# Polarfire SoC register map
Vendor: Microchip; File version: 1.0
CPU: Microchip PolarFire SoC 1.0, little endian
Registers are 32-bit, read-write, reset 0x0 unless marked. A register's access mark holds for its fields unless they carry their own. Offsets are from the block's base; [hi:lo] are bit positions.

## GEM_A_LO (part 1 of 8) — GEM_A_LO Controller
Base 0x20110000
Same registers: GEM_B_LO 0x20112000, GEM_A_HI 0x28110000, GEM_B_HI 0x28112000
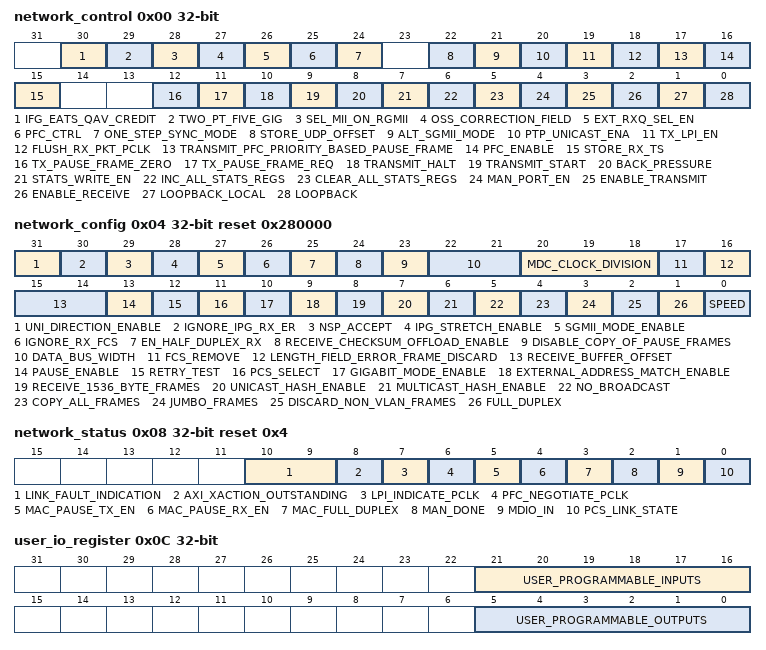
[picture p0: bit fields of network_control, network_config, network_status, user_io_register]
0x00 network_control — The network control register contains general MAC control functions for both receiver and transmitter.
  [30] IFG_EATS_QAV_CREDIT — Setting this bit high modifies the CBS algorithm so the IFG/IPG associated with a transmit frame counts towards its 802.1Qav credit.
  [29] TWO_PT_FIVE_GIG — 2.5G operation selected - setting this bit high drives the speed_mode[3] top level output pin high and also adjusts the link timer in the PCS auto-negotiation block to ensure it delivers 10ms for 2500BASE-X and 1.6ms in SGMII mode, and also ensures int_moderation counts 800ns periods with the speeded up MAC clocks.
  [28] SEL_MII_ON_RGMII — If the RGMII interface is being used, set this bit high to configure the RGMII interface for MII operation (in 802.3br configurations this bit has no effect for the eMAC).
  [27] OSS_CORRECTION_FIELD — 1588 One Step Correction Field Update. Set this bit high to enable updating the correction field of PTP 1588 version 2 sync frames by adding the current TSU timer value.
  [26] EXT_RXQ_SEL_EN — Enable external selection of receive queue. When this bit is high the ext_match1, ext_match2, ext_match3 and ext_match4 inputs will determine which receive queue a frame is routed to. This will be the case regardless of the state of the external address match enable bit 9 of the network config register. Note that receive frames will be dropped unless they are matched by the internal frame filtering functionality. If the external address match enable bit 9 in the network config register is set frames may be matched by an external address match filter as long as one of the ext_match1, ext_match2, ext_match3 and ext_match4 inputs is asserted early enough. When set ext_rxq_sel_en takes precedence over the existing screener functionality. This bit is only relevant if priority queuing is configured.
  [25] PFC_CTRL — Enable multiple PFC pause quantums, one per pause priority.
  [24] ONE_STEP_SYNC_MODE — 1588 One Step Sync Mode. Write 1 to enable. Replace timestamp field in the 1588 header for TX Sync Frames with current TSU timer value.
  [22] STORE_UDP_OFFSET — Store UDP / TCP offset to memory. Setting this bit to one will cause the upper 16-bits of the CRC of every received frame to be replaced with the offset from start of frame to the beginning of the UDP or TCP header. The lower 16-bits of the CRC are replaced with zero and reserved for future use. The offset is measured in units of 2 bytes. Set to zero for normal operation.
  [21] ALT_SGMII_MODE — Alternative sgmii mode. If asserted with sgmii_mode in the network control register the ACK bit is driven before ability detect during transfer of status information from the PHY to the MAC.
  [20] PTP_UNICAST_ENA — Enable detection of unicast PTP unicast frames.
  [19] TX_LPI_EN — Enable LPI transmission when set LPI (low power idle) is immediately transmitted. Depending on configuration LPI is indicated on the GMII, RGMII or MII interface and can be encoded by the PCS used for SGMII. LPI is transmitted even if bit 3 transmit enable is disabled. Setting this bit also sends a pause signal to the transmit datapath. In 802.3br configurations LPI can only be controlled from the pMAC.
  [18] FLUSH_RX_PKT_PCLK — Flush the next packet from the external RX DPRAM. This bit flushes the frame that is the next in line to be pushed out to the AXI interface. Writing one to this bit will only have an effect if the DMA is not currently writing a packet already stored in the DPRAM to memory.
  [17] TRANSMIT_PFC_PRIORITY_BASED_PAUSE_FRAME — Write a one to transmit PFC priority based pause frame. Takes the values stored in the Transmit PFC Pause Register.
  [16] PFC_ENABLE — Enable PFC Priority Based Pause Reception capabilities. Setting this bit will enable PFC negotiation and recognition of priority based pause frames.
  [15] STORE_RX_TS — Store receive time stamp to memory. Setting this bit to one will cause the CRC of every received frame to be replaced with the value of the nanoseconds field of the 1588 timer that was captured as the receive frame passed the message time stamp point (for releases prior to 1p10 bits 31 and 30 of the value written to the CRC field were hardwired to zero, from release 1p10 onwards these bits represent the two least significant seconds bit of the captured timer value). Set to zero for normal operation.
  [12] TX_PAUSE_FRAME_ZERO — Transmit zero quantum pause frame - writing one to this bit causes a pause frame with zero quantum to be transmitted.
  [11] TX_PAUSE_FRAME_REQ — Transmit pause frame - writing one to this bit causes a pause frame to be transmitted.
  [10] TRANSMIT_HALT — Transmit halt - writing one to this bit resets the tx_go variable and halts the dma from reading more transmit frames into the transmit SRAM buffer. Any frames already read into the transmit SRAM will still be transmitted.
  [9] TRANSMIT_START — Start transmission - writing one to this bit starts transmission.
  [8] BACK_PRESSURE — Back pressure if set in 10M or 100M half-duplex mode will force collisions on all received frames. Ignored in gigabit half-duplex mode.
  [7] STATS_WRITE_EN — Write enable for statistics registers - setting this bit to one means the statistics registers can be written for functional test purposes.
  [6] INC_ALL_STATS_REGS — Incremental statistics registers - this bit is write only. Writing a one increments all the statistics registers by one for test purposes.
  [5] CLEAR_ALL_STATS_REGS — Clear statistics registers - this bit is write only. Writing a one clears the statistics registers.
  [4] MAN_PORT_EN — Management port enable - set to one to enable the management port. When zero forces mdio to high impedance state and mdc low.
  [3] ENABLE_TRANSMIT — Transmit enable - when set, it enables the GEM transmitter to send data. When reset transmission will stop immediately, the transmit pipeline and control registers will be cleared and the transmit queue pointer register will reset to point to the start of the transmit descriptor list. This bit needs to be set before bit 9 the start transmission bit. (Setting this bit low resets the transmit queue pointer however reading the transmit queue pointer register through the APB interface may still return an old value until transmission is restarted.)
  [2] ENABLE_RECEIVE — Receive enable - when set, it enables the GEM to receive data. When reset frame reception will stop immediately and the receive pipeline will be cleared. The receive queue pointer register is unaffected.
  [1] LOOPBACK_LOCAL — Loopback local - asserts the loopback_local signal to the system clock generator. Also connects txd to rxd, tx_en to rx_dv and forces full duplex mode. If the GEM configuration contains the PCS then bit 11 of the network configuration register must be set low to disable TBI mode when in internal loopback. rx_clk and tx_clk may malfunction as the GEM is switched into and out of internal loopback. It is important that receive and transmit circuits have already been disabled when making the switch into and out of internal loopback. Local loopback functionality is optional and may not be supported by some instantiations of the GEM.
  [0] LOOPBACK — Loopback - controls the loopback output pin.
0x04 network_config reset 0x280000 — The network configuration register contains functions for setting the mode of operation for the Gigabit Ethernet MAC.
  [31] UNI_DIRECTION_ENABLE — Uni-direction-enable. When low the PCS will transmit idle symbols if the link goes down. When high the PCS can transmit frame data when the link is down.
  [30] IGNORE_IPG_RX_ER — Ignore IPG rx_er. When set rx_er has no effect on the GEMs operation when rx_dv is low. Set this when using the RGMII wrapper in half-duplex mode.
  [29] NSP_ACCEPT — Receive bad preamble. When set frames with non-standard preamble are not rejected (the first byte of preamble needs to be 55 and the last D5, bytes other than 55 or D5 may be inserted in between).
  [28] IPG_STRETCH_ENABLE — IPG stretch enable - when set the transmit IPG can be increased above 96 bit times depending on the previous frame length using the IPG stretch register.
  [27] SGMII_MODE_ENABLE — SGMII mode enable - changes behaviour of the auto-negotiation advertisement and link partner ability registers to meet the requirements of SGMII and reduces the duration of the link timer from 10 ms to 1.6 ms.
  [26] IGNORE_RX_FCS — Ignore RX FCS - when set frames with FCS/CRC errors will not be rejected. FCS error statistics will still be collected for frames with bad FCS and FCS status will be recorded in frame's DMA descriptor. For normal operation this bit must be set to zero.
  [25] EN_HALF_DUPLEX_RX — Enable frames to be received in half-duplex mode while transmitting.
  [24] RECEIVE_CHECKSUM_OFFLOAD_ENABLE — Receive checksum offload enable - when set, the receive checksum engine is enabled. Frames with bad IP, TCP or UDP checksums are discarded.
  [23] DISABLE_COPY_OF_PAUSE_FRAMES — Disable copy of pause frames - set to one to prevent pause frames being copied to memory. When set, neither control frames with type id 8808, nor pause frames with destination address 010000c28001 are copied to memory, this functionality was enhanced in release 1p09. Note that valid pause frames received will still increment pause statistics and pause the transmission of frames as required.
  [22:21] DATA_BUS_WIDTH — Data bus width - set according to AMBA (AHB/AXI) or external FIFO data bus width. The reset value for this can be changed by defining a new value for gem_dma_bus_width_def in gem_defs. Only valid bus widths may be written if the system is configured to a maximum width less than 128-bits., :00: 32 bit data bus width, :01: 64 bit AMBA (AHB/AXI) data bus width, :10: 128 bit AMBA (AHB/AXI) data bus width, :11: invalid, :Note. The reset value of this field is equal to the gem_dma_bus_width_def define, which is user configurable.
  [20:18] MDC_CLOCK_DIVISION — MDC clock division - set according to pclk speed. These three bits determine the number pclk will be divided by to generate MDC. For conformance with the 802.3 specification, MDC must not exceed 2.5 MHz (MDC is only active during MDIO read and write operations). The reset value for this can be changed by defining a new value for gem_mdc_clock_div in gem_defs.v, :000: divide pclk by 8 (pclk up to 20 MHz), :001: divide pclk by 16 (pclk up to 40 MHz), :010: divide pclk by 32 (pclk up to 80 MHz), :011: divide pclk by 48 (pclk up to 120MHz), :100: divide pclk by 64 (pclk up to 160 MHz), :101: divide pclk by 96 (pclk up to 240 MHz), :110: divide pclk by 128 (pclk up to 320 MHz), :111: divide pclk by 224 (pclk up to 540 MHz)., :Note. The reset value of this field is equal to the gem_mdc_clock_div define, which is user configurable.
  [17] FCS_REMOVE — FCS remove - setting this bit will cause received frames to be written to memory without their frame check sequence (last 4 bytes). The frame length indicated will be reduced by four bytes in this mode.
  [16] LENGTH_FIELD_ERROR_FRAME_DISCARD — Length field error frame discard - setting this bit causes frames with a measured length shorter than the extracted length field (as indicated by bytes 13 and 14 in a non-VLAN tagged frame) to be discarded. This only applies to frames with a length field less than 0x0600.
  [15:14] RECEIVE_BUFFER_OFFSET — Receive buffer offset - indicates the number of bytes by which the received data is offset from the start of the receive buffer. Note that when the define gem_pbuf_rsc has been set then these bits cannot be used.
  [13] PAUSE_ENABLE — Pause enable - when set, transmission will pause if a non-zero 802.3 classic pause frame is received and PFC has not been negotiated.
  [12] RETRY_TEST — Retry test - must be set to zero for normal operation. If set to one the backoff between collisions will always be one slot time. Setting this bit to one helps test the too many retries condition. Also used in the pause frame tests to reduce the pause counter's decrement time from 512 bit times, to every rx_clk cycle.
  [11] PCS_SELECT — PCS select - selects between MII/GMII and TBI. Must be set for SGMII operation., :0: GMII/MII interface enabled, TBI disabled, :1: TBI enabled, GMII/MII disabled, :(in 802.3br configurations this bit must be set identically in the eMAC and pMAC)
  [10] GIGABIT_MODE_ENABLE — Gigabit mode enable - setting this bit configures the GEM for 1000 Mbps operation., :0: 10/100 operation using MII or TBI interface, :1: Gigabit operation using GMII or TBI interface, :(in 802.3br configurations this bit must be set identically in the eMAC and pMAC)
  [9] EXTERNAL_ADDRESS_MATCH_ENABLE — External address match enable - when set the external address match interface can be used to copy frames to memory.
  [8] RECEIVE_1536_BYTE_FRAMES — Receive 1536 byte frames - setting this bit means the GEM will accept frames up to 1536 bytes in length. Normally the GEM would reject any frame above 1518 bytes.
  [7] UNICAST_HASH_ENABLE — Unicast hash enable - when set, unicast frames will be accepted when the 6 bit hash function of the destination address points to a bit that is set in the hash register.
  [6] MULTICAST_HASH_ENABLE — Multicast hash enable - when set, multicast frames will be accepted when the 6 bit hash function of the destination address points to a bit that is set in the hash register.
  [5] NO_BROADCAST — No broadcast - when set to logic one, frames addressed to the broadcast address of all ones will not be accepted.
  [4] COPY_ALL_FRAMES — Copy all frames - when set to logic one, all valid frames will be accepted.
  [3] JUMBO_FRAMES — Jumbo frames - set to one to enable jumbo frames up to 'gem_jumbo_max_length bytes to be accepted. The default length is 10,240 bytes.
  [2] DISCARD_NON_VLAN_FRAMES — Discard non-VLAN frames - when set only VLAN tagged frames will be passed to the address matching logic.
  [1] FULL_DUPLEX — Full duplex - if set to logic one, the transmit block ignores the state of collision and carrier sense and allows receive while transmitting. Also controls the half_duplex pin.
  [0] SPEED — Speed - set to logic one to indicate 100Mbps operation, logic zero for 10Mbps. The value of this pin is reflected on the speed_mode[0] output pin (in 802.3br configurations this bit has no effect for the eMAC).
0x08 network_status ro reset 0x4 — The network status register returns status information with respect to the PHY management MDIO interface, the PCS, priority flow control, LPI and other status.
  [10:9] LINK_FAULT_INDICATION — For 2.5GBASE-X operation these two bits return the state of link_fault in the LFSM defined in Figure 46-11 of IEEE 802.3:, : 00 - OK, : 01 - local fault, : 10 - remote fault, : 11 - link interruption, :If the link fault state machine is not enabled (by setting the 2.5G, AN enable, uni directional enable and tbi control bits) these two bits are set to zero.
  [8] AXI_XACTION_OUTSTANDING — Outstanding AXI Transactions - This status bit is set when one or more AXI read or write transactions have been issued by the DUT but the responses have not yet been fully collected.
  [7] LPI_INDICATE_PCLK — LPI Indication - Low power idle has been detected on receive. This bit is set when LPI is detected and reset when normal idle is detected. An interrupt is generated when the state of this bit changes.
  [6] PFC_NEGOTIATE_PCLK — Set when PFC Priority Based Pause has been negotiated.
  [5] MAC_PAUSE_TX_EN — PCS auto-negotiation pause transmit resolution.
  [4] MAC_PAUSE_RX_EN — PCS auto-negotiation pause receive resolution.
  [3] MAC_FULL_DUPLEX — PCS auto-negotiation duplex resolution. Set to one if the resolution function determines that both devices are capable of full duplex operation. If zero half-duplex operation is possible as long as bit 0 (PCS link state) is also one.
  [2] MAN_DONE — The PHY management logic is idle (i.e. has completed).
  [1] MDIO_IN — Returns status of the mdio_in pin.
  [0] PCS_LINK_STATE — Returns status of PCS link state. If auto-negotiation is disabled this returns the synchronisation status. If auto-negotiation is enabled it is set in the LINK_OK state as long as a compatible duplex mode is resolved, it is always set in the LINK_OK state in SGMII mode.
0x0C user_io_register — The GEM design provides up to 16 inputs and 16 outputs so that the I/O may be read or set under the control of the processor interface. The number of inputs and outputs are set by the user_in_width and user_out_width verilog macro defines. If the user I/O is disabled as a configuration option, this address space is defined as reserved, and hence will be a read-only register of the value 0x0. If enabled, the number of inputs and outputs can be configured separately. The first output will be represented in bit 0 of the user I/O register, the second output will use bit 1 and so on. The first input will be represented in bit 16 of the user I/O register, the second input will use bit 17 and so on.
  [21:16] USER_PROGRAMMABLE_INPUTS ro — User programmable inputs - the upper 16 bits of this register are used to monitor the state of the user inputs. A logic one read from a bit in this range will correspond to the input being in a high state. A logic zero read from a bit in this range will correspond to the input being in a low state. Any unused bits will be read as 0. Writing to any bits in this range will have no functional effect.
  [5:0] USER_PROGRAMMABLE_OUTPUTS — User programmable outputs - the lower 16 bits of this register are used to control the state of the user outputs. A logic one written to a bit in this range will cause the corresponding output to be set high. A logic zero written to a bit in this range shall cause the corresponding output to be forced low. Any unused bits will be read as logic zero. Writing to any unused bits in this range will have no functional effect.
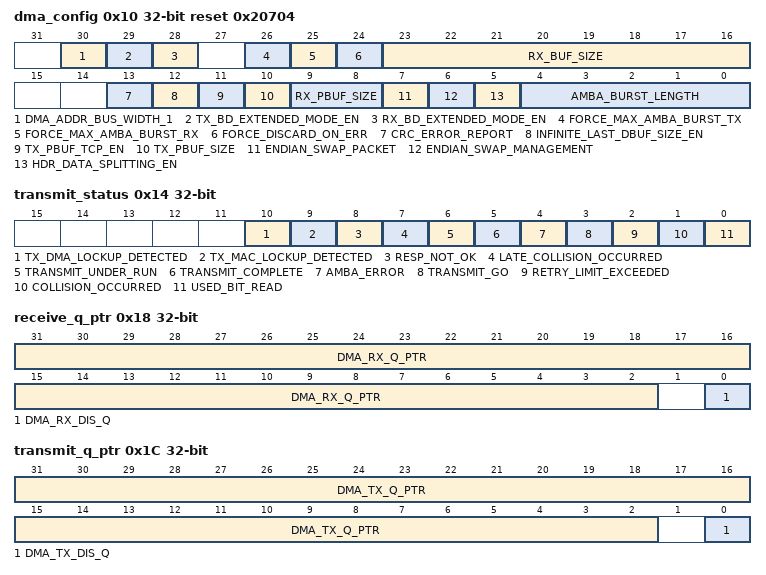
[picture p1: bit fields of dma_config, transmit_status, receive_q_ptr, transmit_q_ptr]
0x10 dma_config reset 0x20704 — DMA Configuration Register
  [30] DMA_ADDR_BUS_WIDTH_1 — DMA address bus width. 0 = 32b, 1 = 64b.
  [29] TX_BD_EXTENDED_MODE_EN — Enable TX extended BD mode. See TX BD control register definition for description of feature.
  [28] RX_BD_EXTENDED_MODE_EN — Enable RX extended BD mode. See RX BD control register definition for description of feature.
  [26] FORCE_MAX_AMBA_BURST_TX — Force max length bursts on TX. Force the TX DMA to always issue max length bursts on EOP (end of packet) or EOB (end of buffer) transfers as defined by bits 4:0 of this register, even when there is less than max burst data bytes to read. Residual data read is ignored. AHB only - does not apply on AXI bursts (prior to release 1p10) or bursts that break 1k boundary rule - supported on AXI from release 1p10.
  [25] FORCE_MAX_AMBA_BURST_RX — Force max length bursts on RX. Force the RX DMA to always issue max length bursts on EOP (end of packet) or EOB (end of buffer) transfers, even if there is less than max burst real packet data required to write. Any extra bytes of pad data is set to 0x00. AHB only - does not apply on AXI bursts (prior to release 1p10) or bursts that break 1k boundary rule - supported on AXI from release 1p10.
  [24] FORCE_DISCARD_ON_ERR — Auto Discard RX frames during lack of resource. When set, the GEM DMA will automatically discard the next frame (that is the oldest frame) from the receiver packet buffer memory when a receive buffer descriptor is read with its used bit set. When low, then received frames will remain to be stored in the SRAM based packet buffer until AMBA (AHB/AXI) buffer resource next becomes available. In this case if the SRAM memory fills up then there will be a receive overflow condition and the most recently received frame (that is the newest) will be discarded. A write to this bit is ignored if the DMA is not configured in the packet buffer full store and forward mode.
  [23:16] RX_BUF_SIZE — DMA receive buffer size in external AMBA (AHB/AXI) system memory. The value defined by these bits determines the size of buffer to use in main system memory when writing received data. The value is defined in multiples of 64 bytes., :0x01 corresponds to buffers of 64 bytes, :0x02 corresponds to 128 bytes etc., :For example:, :0x02: 128 byte., :0x18: 1536 byte (1*max length frame/buffer), :0xA0: 10240 byte (1*10K jumbo frame/buffer), :0xFF: 16320 byte , :Note that this value should never be written as zero., :Note. The reset value of this field is equal to the gem_rx_buffer_length_def define, which is user configurable.
  [13] CRC_ERROR_REPORT — When the bit is set, bit 16 of the receive buffer descriptor will represent FCS/CRC error (only if frames with FCS are copied to memory as enabled by bit 26 in the network config register). When this bit is clear, bit 16 of the receive buffer descriptor will represent the Canonical format indicator (CFI) bit as extracted from the receive frame (if the receive buffer descriptor is pointing to the last data buffer of the receive frame and the received frame was VLAN tagged).
  [12] INFINITE_LAST_DBUF_SIZE_EN — Forces the receive DMA to consider the data buffer pointed to by last descriptor in the descriptor list to be of elastic size (the last descriptor is the one with its wrap bit set). This means the first buffer pointed to in the list will always contain the beginning of a frame (this helps if there is a desire to build custom logic that interfaces with the receive buffer directly without software intervention). When set the rx_buf_size bits 23:16 in the dma configuration register are ignored for the last receive buffer in the descriptor list and data will be written into the buffer sequentially until the frame is completely received and the buffer descriptor status will be updated with the frame length as normal.
  [11] TX_PBUF_TCP_EN — Transmitter IP, TCP and UDP checksum generation offload enable (not supported when in TX Partial Store and Forward mode). When set, the transmitter checksum generation engine is enabled, to calculate and substitute checksums for transmit frames. When clear, frame data is unaffected. If the GEM is not configured to use the DMA packet buffer, this bit is not implemented and will be treated as reserved, read as 0, ignored on write.
  [10] TX_PBUF_SIZE — Transmitter packet buffer memory size select. Having this bit at zero halves the amount of memory used for the transmit packet buffer. This reduces the amount of memory used by the GEM. It is important to set this bit to one if the full configured physical memory is available. The value in brackets below represents the size that would result for the default maximum configured memory size of 4 Kbytes., :1: Use full configured addressable space (4 Kb), :0: Do not use top address bit (2 Kb), :If the GEM is not configured to use the DMA packet buffer, this bit is not implemented and will be treated as reserved, read as 0, ignored on write., :Note. The reset value of this field is equal to the gem_tx_pbuf_size_def define, which is user configurable.
  [9:8] RX_PBUF_SIZE — Receiver packet buffer memory size select. Having these bits at less than 11 reduces the amount of memory used for the receive packet buffer. This reduces the amount of memory used by the GEM. It is important to set these bits both to one if the full configured physical memory is available. The value in brackets below represents the size that would result for the default maximum configured memory size of 8 Kbytes., :11: Use full configured addressable space (8 Kb), :10: Do not use top address bit (4 Kb), :01: Do not use top two address bits (2 Kb), :00: Do not use top three address bits (1 Kb), :If the GEM is not configured to use the DMA packet buffer, these bits are not implemented and will be treated as reserved, read as 0, ignored on write., :Note. The reset value of this field is equal to the gem_rx_pbuf_size_def define, which is user configurable.
  [7] ENDIAN_SWAP_PACKET — endian swap mode enable for packet data accesses. When set, selects swapped endianism for AMBA (AHB/AXI) transfers. When clear, selects little endian mode.
  [6] ENDIAN_SWAP_MANAGEMENT — endian swap mode enable for management descriptor accesses. When set, selects swapped endianism for AMBA (AHB/AXI) transfers. When clear, selects little endian mode.
  [5] HDR_DATA_SPLITTING_EN — Enable header data Splitting. When set, receive frames will be forwarded to main memory using a minimum of two DMA data buffers. The first X data buffers will contain the frame header, consisting of the Ethernet,VLAN,(IPv4 or IPv6),(TCP or UDP). X= (frame header size divided by rx_buf_size as defined in bits 23:16 of this register). The last Y data buffers will contain the frame payload. Y= (frame payload size divided by rx_buf_size). Note that for non VLAN/IP/TCP/UDP frames, the header will always be 14 bytes. When this feature is disabled, the frame is forwarded to main memory in blocks of rx_buf_size.
  [4:0] AMBA_BURST_LENGTH — Selects the burst length to use on the AMBA (AHB/AXI) when transferring frame data. Not used for DMA management operations and only used where space and data size allow and respecting AXI/AHB burst boundary rules. One-hot priority encoding enforced automatically on register writes as follows, where x represents don't care:, :1xxxx: Attempt to use bursts of up to 16., :01xxx: Attempt to use bursts of up to 8., :001xx: Attempt to use bursts of up to 4., :0001x: Always use SINGLE bursts., :00001: Always use SINGLE bursts., :00000: Attempt to use bursts of up to 256.
0x14 transmit_status — This register, when read, provides details of the status of the transmit path. Once read, individual bits may be cleared by writing 1 to them. It is not possible to set a bit to 1 by writing to the register.
  [10] TX_DMA_LOCKUP_DETECTED — TX DMA lockup detected - set when lockup has been detected the transmit DMA lockup monitor.
  [9] TX_MAC_LOCKUP_DETECTED — TX MAC lockup detected - set when lockup has been detected by the lockup monitor on the MAC transmit path.
  [8] RESP_NOT_OK — bresp/hresp not OK - set when the DMA block sees bresp/hresp not OK. Cleared by writing a one to this bit.
  [7] LATE_COLLISION_OCCURRED — Late collision occurred - only set if the condition occurs in gigabit mode, as retry is not attempted. Cleared by writing a one to this bit.
  [6] TRANSMIT_UNDER_RUN — Transmit under run - this bit is set if the transmitter was forced to terminate a frame that it had already began transmitting due to further data being unavailable. This bit is set if a transmitter status write back has not completed when another status write back is attempted. When using the DMA interface configured for internal FIFO mode, this bit is also set when the transmit DMA has written the SOP data into the FIFO and either the AHB bus was not granted in time for further data, or because an AHB not OK response was returned, or because a used bit was read. When using the DMA interface configured for packet buffer mode, this bit will never be set. When using the external FIFO interface, this bit is also set when the tx_r_underflow input is asserted during a frame transfer. Cleared by writing a 1.
  [5] TRANSMIT_COMPLETE — Transmit complete - set when a frame has been transmitted. Cleared by writing a one to this bit.
  [4] AMBA_ERROR — Transmit frame corruption due to AMBA (AHB/AXI) errors. Set if an error occurs whilst midway through reading transmit frame from external memory including HRESP(AHB), RRESP or BRESP(AXI) errors and buffers exhausted mid frame (if the buffers run out during transmission of a frame then transmission stops, FCS shall be bad and tx_er asserted). Also set in DMA packet buffer mode if single frame is too large for configured packet buffer memory size. Some AXI errors cause immediate reset of the transmit MAC datapath, in these cases tx_er will not be asserted and this bit will not be set. Cleared by writing a one to this bit.
  [3] TRANSMIT_GO ro — Transmit go - if high transmit is active. When using the exposed FIFO interface, this bit represents the transmit enable bit (bit 3) of the network control register. When using the DMA interface this bit represents the tx_go variable as specified in the transmit buffer description.
  [2] RETRY_LIMIT_EXCEEDED — Retry limit exceeded - cleared by writing a one to this bit.
  [1] COLLISION_OCCURRED — Collision occurred - set by the assertion of collision. Cleared by writing a one to this bit. When operating in 10/100 mode, this status indicates either a collision or a late collision. In gigabit mode, this status is not set for a late collision.
  [0] USED_BIT_READ — Used bit read - set when a transmit buffer descriptor is read with its used bit set. Cleared by writing a one to this bit.
0x18 receive_q_ptr — This register holds the start address of the receive buffer queue (receive buffers descriptor list). The receive buffer queue base address must be initialized before receive is enabled through bit 2 of the network control register. Once reception is enabled, any write to the receive buffer queue base address register is ignored. Reading this register returns the location of the descriptor currently being accessed. This value increments as buffers are used. Software should not use this register for determining where to remove received frames from the queue as it constantly changes as new frames are received. Software should instead work its way through the buffer descriptor queue checking the used bits. In terms of AMBA (AHB/AXI) operation, the receive descriptors are read from memory using a single 32bit AHB/AXI access. When the datapath is configured at 64bit or 128bit, the receive descriptors should be aligned at 64-bit boundaries and each pair of 32-bit descriptors is written to using a single 64bit AHB/AXI access. For 32bit datapaths, the receive descriptors should be aligned at 32-bit boundaries and are written to using two individual non sequential 32-bit accesses.
  [31:2] DMA_RX_Q_PTR — Receive buffer queue base address - written with the address of the start of the receive queue.
  [0] DMA_RX_DIS_Q — Disable queue if set to 1. This can be used to reduce the number of active queues and should only be changed while receive is not enabled.
0x1C transmit_q_ptr — This register holds the start address of the transmit buffer queue (transmit buffers descriptor list). The transmit buffer queue base address register must be initialized before transmit is started through bit 9 of the network control register. Once transmission has started, any write to the transmit buffer queue base address register is illegal and therefore ignored. Note that due to clock boundary synchronization, it takes a maximum of four pclk cycles from the writing of the transmit start bit before the transmitter is active. Writing to the transmit buffer queue base address register during this time may produce unpredictable results. Reading this register returns the location of the descriptor currently being accessed. Because the DMA can store data for multiple frames at once, this may not necessarily be pointing to the current frame being transmitted. In terms of AMBA AHB/AXI operation, the transmit descriptors are written to memory using a single 32bit AHB access. When the datapath is configured as 64bit or 128bit, the transmit descriptors should be aligned at 64-bit boundaries and each pair of 32-bit descriptors is read from memory using a single AHB/AXI access. For 32bit datapaths, the descriptors should be aligned at 32-bit boundaries and the descriptors are read from memory using two individual 32-bit non sequential accesses.
  [31:2] DMA_TX_Q_PTR — Transmit buffer queue base address - written with the address of the start of the transmit queue.
  [0] DMA_TX_DIS_Q — Disable queue if set to 1. This can be used to reduce the number of active queues and should only be changed while transmit is not enabled.
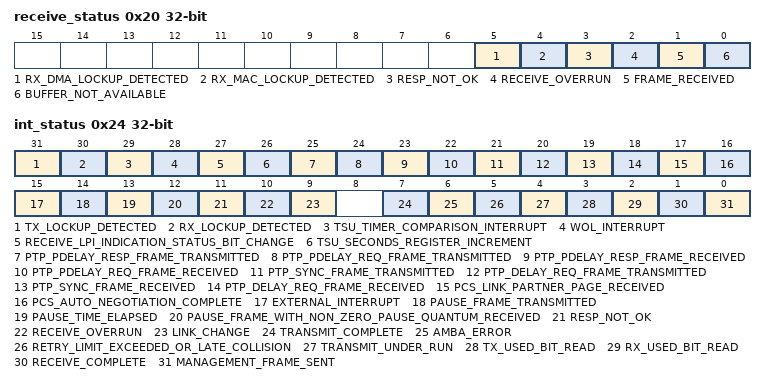
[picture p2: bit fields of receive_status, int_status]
0x20 receive_status — This register, when read provides details of the status of the receive path. Once read, individual bits may be cleared by writing 1 to them. It is not possible to set a bit to 1 by writing to the register.
  [5] RX_DMA_LOCKUP_DETECTED — RX DMA lockup detected - set when lockup has been detected the receive DMA lockup monitor.
  [4] RX_MAC_LOCKUP_DETECTED — RX MAC lockup detected - set when lockup has been detected by the lockup monitor on the MAC receive path.
  [3] RESP_NOT_OK — bresp/hresp not OK - set when the DMA block sees bresp/hresp not OK. Cleared by writing a one to this bit.
  [2] RECEIVE_OVERRUN — Receive overrun - this bit is set if either the gem_dma RX FIFO or external RX FIFO were unable to store the receive frame due to a FIFO overflow, or if the receive status, reported by the gem_rx module to the gem_dma was not taken at end of frame. This bit is also set in DMA packet buffer mode if the packet buffer overflows. For DMA operation the buffer will be recovered if an overrun occurs. This bit is cleared by writing a one to it.
  [1] FRAME_RECEIVED — Frame received - one or more frames have been received and placed in memory. Cleared by writing a one to this bit.
  [0] BUFFER_NOT_AVAILABLE — Buffer not available - an attempt was made to get a new buffer and the pointer indicated that it was owned by the processor. The DMA will reread the pointer each time an end of frame is received until a valid pointer is found. This bit is set following each descriptor read attempt that fails, even if consecutive pointers are unsuccessful and software has in the meantime cleared the status flag. Cleared by writing a one to this bit.
0x24 int_status — If not configured for priority queuing, the GEM generates a single interrupt. This register indicates the source of this interrupt. The corresponding bit in the mask register must be clear for a bit to be set. If any bit is set in this register the ethernet_int signal will be asserted. For test purposes each bit can be set or reset by writing to the interrupt mask register. The default configuration is shown below whereby all bits are reset to zero on read. Changing the validity of the 'gem_irq_read_clear define will instead require a one to be written to the appropriate bit in order to clear it. In this mode reading has no effect on the status of the bit.
  [31] TX_LOCKUP_DETECTED — TX lockup detection - set when lockup has been detected by any of the lockup monitors on the transmit datapath.
  [30] RX_LOCKUP_DETECTED — RX lockup detection - set when lockup has been detected by any of the lockup monitors on the receive datapath.
  [29] TSU_TIMER_COMPARISON_INTERRUPT — TSU timer comparison interrupt. Indicates when TSU timer count value is equal to programmed value.
  [28] WOL_INTERRUPT — WOL interrupt. Indicates a WOL event has been received.
  [27] RECEIVE_LPI_INDICATION_STATUS_BIT_CHANGE
  [26] TSU_SECONDS_REGISTER_INCREMENT — TSU seconds register increment indicates the register has incremented. Cleared on read.
  [25] PTP_PDELAY_RESP_FRAME_TRANSMITTED — PTP pdelay_resp frame transmitted indicates a PTP pdelay_resp frame has been transmitted. Cleared on read.
  [24] PTP_PDELAY_REQ_FRAME_TRANSMITTED — PTP pdelay_req frame transmitted indicates a PTP pdelay_req frame has been transmitted. Cleared on read.
  [23] PTP_PDELAY_RESP_FRAME_RECEIVED — PTP pdelay_resp frame received indicates a PTP pdelay_resp frame has been received. Cleared on read.
  [22] PTP_PDELAY_REQ_FRAME_RECEIVED — PTP pdelay_req frame received indicates a PTP pdelay_req frame has been received. Cleared on read.
  [21] PTP_SYNC_FRAME_TRANSMITTED — PTP sync frame transmitted indicates a PTP sync frame has been transmitted. Cleared on read.
  [20] PTP_DELAY_REQ_FRAME_TRANSMITTED — PTP delay_req frame transmitted indicates a PTP delay_req frame has been transmitted. Cleared on read.
  [19] PTP_SYNC_FRAME_RECEIVED — PTP sync frame received indicates a PTP sync frame has been received. Cleared on read.
  [18] PTP_DELAY_REQ_FRAME_RECEIVED — PTP delay_req frame received indicates a PTP delay_req frame has been received. Cleared on read.
  [17] PCS_LINK_PARTNER_PAGE_RECEIVED — PCS link partner page received - set when a new base page or next page is received from the link partner. The first time this interrupt is received, it will indicate base page received and subsequent reads will indicate next pages. The next page and base page registers should only be read when this interrupt is signalled. For next pages, the link partner next page register should be read first to avoid the register being over written. This interrupt also indicates when the host should write a new page into the next page register. If further next page exchange is only required by the link partner, this register should be written with a null message page (0x2001). Cleared on read.
  [16] PCS_AUTO_NEGOTIATION_COMPLETE — PCS auto-negotiation complete - set once the internal PCS layer has completed auto-negotiation. Cleared on read.
  [15] EXTERNAL_INTERRUPT — External interrupt - set when a rising edge has been detected on the ext_interrupt_in input pin. Cleared on read.
  [14] PAUSE_FRAME_TRANSMITTED — Pause frame transmitted - indicates a pause frame has been successfully transmitted after being initiated from the network control register or from the tx_pause control pin. Cleared on read.
  [13] PAUSE_TIME_ELAPSED — Pause Time elapsed - set when either the pause time register at address 0x38 decrements to zero, or when a valid pause frame is received with a zero pause quantum field. Not set for PFC pause frames. Cleared on read.
  [12] PAUSE_FRAME_WITH_NON_ZERO_PAUSE_QUANTUM_RECEIVED — Pause frame with non-zero pause quantum received - indicates a valid legacy pause frame with a non-zero pause quantum field has been received or any valid PFC pause frame has been received. Cleared on read.
  [11] RESP_NOT_OK — bresp/hresp not OK - set when the DMA block sees bresp/hresp not OK. Cleared on read.
  [10] RECEIVE_OVERRUN — Receive overrun - set when the receive overrun status bit gets set. Cleared on read.
  [9] LINK_CHANGE — Link change - set when the PCS link status changes. If auto-negotiation is enabled then link status goes high when it completes. If AN is disabled link status goes high when synchronization is achieved. If 802.3cb link fault signalling is enabled a link change interrupt is triggered when the link fault indication as reported in the network status register changes. Cleared on read.
  [7] TRANSMIT_COMPLETE — Transmit complete - set when a frame has been transmitted. Cleared on read.
  [6] AMBA_ERROR — Transmit frame corruption due to AMBA (AHB/AXI) error. Set if an error occurs whilst midway through reading transmit frame from external system memory, including HRESP errors(AHB), RRESP or BRESP(AXI) errors and buffers exhausted mid frame (if the buffers run out during transmission of a frame then transmission stops, FCS shall be bad and tx_er asserted). Also set in DMA packet buffer mode if single frame is too large for configured packet buffer memory size. Cleared on a read.
  [5] RETRY_LIMIT_EXCEEDED_OR_LATE_COLLISION — Retry limit exceeded or late collision - transmit error. Late collision will only cause this status bit to be set in gigabit mode (as a retry is not attempted). Cleared on read.
  [4] TRANSMIT_UNDER_RUN — Transmit under run - this interrupt is set if the transmitter was forced to terminate a frame that it has already began transmitting due to further data being unavailable. If an under run occurs, the transmitter will force bad crc and tx_er high. This interrupt is set if a transmitter status write back has not completed when another status write back is attempted. When using the DMA interface configured for internal FIFO mode, this interrupt is also set when the transmit DMA has written the SOP data into the FIFO and either the AHB bus was not granted in time for further data, or because an AHB/AXI error response was returned by the connected slave, or because a used bit was read. When using the DMA interface configured for packet buffer mode, this bit will never be set. When using the external FIFO interface, this interrupt is also set when the tx_r_underflow input was asserted during a frame transfer. Cleared on read.
  [3] TX_USED_BIT_READ — TX used bit read - set when a transmit buffer descriptor is read with its used bit set. Cleared on read.
  [2] RX_USED_BIT_READ — RX used bit read - set when a receive buffer descriptor is read with its used bit set. Cleared on read.
  [1] RECEIVE_COMPLETE — Receive complete - a frame has been stored in memory. Cleared on read.
  [0] MANAGEMENT_FRAME_SENT — Management frame sent - the PHY management register has completed its operation. Cleared on read.
